# TLE985x register map
Vendor: Infineon Technologies AG; Series: MOTIX MCU; File version: 1.6
CPU: CM0 r0p0, little endian, no MPU, no FPU, 2 interrupt priority bits
Registers are 32-bit, read-write, no defined reset value unless marked. A register's access mark holds for its fields unless they carry their own. Offsets are from the block's base; [hi:lo] are bit positions; {n}, {i} and the like mark numbered series; 'fields as' and 'values as' point back to an identical list.

## ADC2
Base 0x4801C000
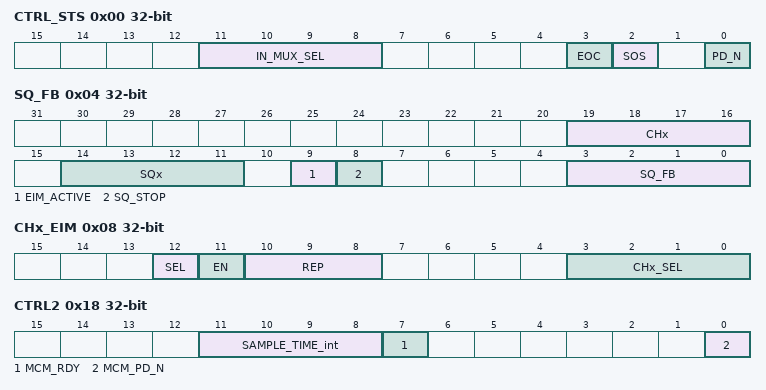
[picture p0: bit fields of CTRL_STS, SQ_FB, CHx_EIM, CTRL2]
0x00 CTRL_STS access per field — ADC2 Control and Status Register
  [11:8] IN_MUX_SEL rw — Channel for software mode
    {v}=CH{v}_EN (Channel {v} enable) (v=0..8)
  [3] EOC ro — ADC2 End of Conversion in software mode
    0=Pending (conversion still running); 1=Finished (conversion has finished)
  [2] SOS rw — ADC2 Start of Sampling/Conversion (software mode)
    0=Disable (no conversion is started); 1=Enable (conversion is started)
  [0] PD_N rw — ADC2 Power Down Signal
    0=POWER_DOWN (ADC2 is powered down); 1=ACTIVE (ADC2 is switched on)
0x04 SQ_FB ro — Sequencer Feedback Register
  [19:16] CHx — Current active ADC2 Channel (in normal mode)
    {v}=CH{v} (Channel {v}) (v=0..8)
  [14:11] SQx — Current active ADC2 Sequence (in normal mode)
    {v}=SQ{v} (Sequence {v}) (v=0..8); 9=SQ9 (Startup sequence)
  [9] EIM_ACTIVE — ADC2 EIM active
    0=not_active (EIM not active); 1=active (EIM active)
  [8] SQ_STOP — ADC2 Sequencer Stop Signal for DPP
    0=DPP_Running (Postprocessing Sequencer in running mode); 1=DPP_Stopped (Postprocessing Sequencer stopped / Software Mode entered)
  [3:0] SQ_FB — Current Sequence that caused software mode
    {v}=SQ{v} (Sequence {v}) (v=0..8); 11=CH_MASK (Sequence was 0 only after masking; SWM not entered); 12=SUSPEND (Debug Suspend Mode)
0x08 CHx_EIM — Channel Settings Bits for Exceptional Interrupt Measurement
  [12] SEL — Exceptional interrupt measurement (EIM) Trigger select
    0=GPT12PISEL_T3_GPT12_SEL (Signal according to SCU_GPT12PISEL.T3_GPT12SEL setting); 1=CP_clk (Charge-pump clock)
  [11] EN — Exceptional interrupt measurement (EIM) Trigger Event enable
    0=DISABLE (start of EIM disabled); 1=ENABLE (start of IEM enabled)
  [10:8] REP — Repeat count for exceptional interrupt measurement (EIM)
    0=Measurement (minimum or continuous measurement as long as trigger signals stays high, 1 / continuous SOC generated for ADC8); 1=Measurements (2 SOC generated for ADC8); 2=Measurements (4 SOC generated for ADC8); 3=Measurements (8 SOC generated for ADC8); 4=Measurements (16 SOC generated for ADC8); 5=Measurements (32 SOC generated for ADC8); 6=Measurements (64 SOC generated for ADC8); 7=Measurements (128 SOC generated for ADC8)
  [3:0] CHx_SEL — Channel set for exceptional interrupt measurement (EIM)
    {v}=CH{v}_EN (Channel {v} enable) (v=0..8)
0x10 MAX_TIME — Maximum Time for Software Mode
  [7:0] MAX_TIME — Maximum Time in Software Mode
    0=min (Software mode is not entered); 1=Software mode is active for 3 clock cycles; 255=max (Software mode is active for 257 clock cycles (typ. 12.85 us))
0x14 CTRL1 — Measurement Unit Control Register 1
  [8:0] CALIB_EN_8_0 — Calibration Enable for Channels 8 to 0
    1=CH0_EN (Channel 0 calibration enable); 2=CH1_EN (Channel 1 calibration enable); 4=CH2_EN (Channel 2 calibration enable); 8=CH3_EN (Channel 3 calibration enable); 16=CH4_EN (Channel 4 calibration enable); 32=CH5_EN (Channel 5 calibration enable); 64=CH6_EN (Channel 6 calibration enable); 128=CH7_EN (Channel 7 calibration enable); 0x100=CH8_EN (Channel 8 calibration enable)
0x18 CTRL2 access per field — Measurement Unit Control Register 2
  [11:8] SAMPLE_TIME_int rw — Sample time of ADC2
    0=MICLK4 (4 MI_CLK clock periods); 1=MICLK6 (6 MI_CLK clock periods); 2=MICLK8 (8 MI_CLK clock periods); 3=MICLK10 (10 MI_CLK clock periods); 4=MICLK12 (12 MI_CLK clock periods (default)); 5=MICLK14 (14 MI_CLK clock periods); 6=MICLK16 (16 MI_CLK clock periods); 7=MICLK18 (18 MI_CLK clock periods); 8=MICLK20 (20 MI_CLK clock periods); 9=MICLK22 (22 MI_CLK clock periods)
  [7] MCM_RDY ro — Ready Signal for MCM after Power On or Reset
    0=MCM_Not_Ready (Measurement Core Module in startup phase); 1=MCM_Ready (Measurement Core Module start-up phase finished)
  [0] MCM_PD_N rw — Power Down Signal for MCM
    0=MCM_Disabled (Measurement Core Module disabled); 1=MCM_Enabled (Measurement Core Module enabled)
0x1C CTRL4 — Measurement Unit Control Register 4
  [8:0] FILT_OUT_SEL_8_0 — Output Filter Selection for Channels 0 to 8
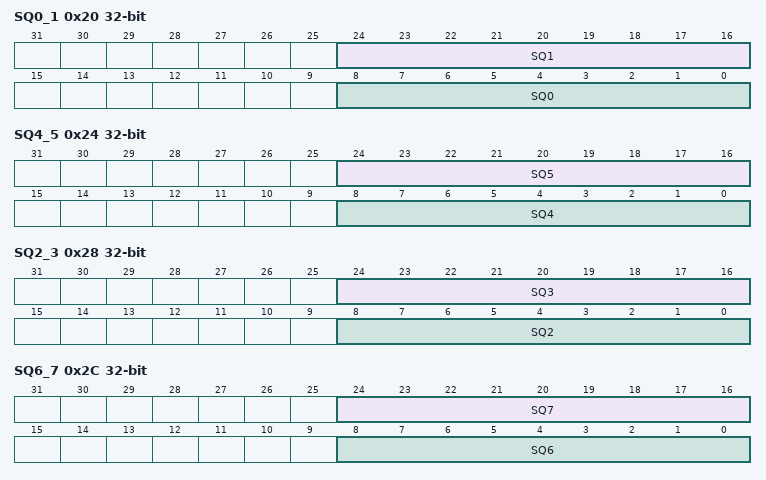
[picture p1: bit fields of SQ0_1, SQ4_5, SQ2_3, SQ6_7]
0x20 SQ0_1 — Measurement Channel Enable Bits for Sequence 0-1
  [24:16] SQ1 — Sequence 1 channel enable
    1=CH0_EN (Channel 0 enable); 2=CH1_EN (Channel 1 enable); 4=CH2_EN (Channel 2 enable); 8=CH3_EN (Channel 3 enable); 16=CH4_EN (Channel 4 enable); 32=CH5_EN (Channel 5 enable); 64=CH6_EN (Channel 6 enable); 128=CH7_EN (Channel 7 enable); 0x100=CH8_EN (Channel 8 enable)
  [8:0] SQ0 — Sequence 0 channel enable
    values as SQ1
0x24 SQ4_5 — Measurement Channel Enable Bits for Sequence 4 - 5
  [24:16] SQ5 — Sequence 5 channel enable
    values as SQ0_1.SQ1
  [8:0] SQ4 — Sequence 4 channel enable
    values as SQ0_1.SQ1
0x28 SQ2_3 — Measurement Channel Enable Bits for Sequence 2-3
  [24:16] SQ3 — Sequence 3 channel enable
    values as SQ0_1.SQ1
  [8:0] SQ2 — Sequence 2 channel enable
    values as SQ0_1.SQ1
0x2C SQ6_7 — Measurement Channel Enable Bits for Sequence 6 - 7
  [24:16] SQ7 — Sequence 7 channel enable
    values as SQ0_1.SQ1
  [8:0] SQ6 — Sequence 6 channel enable
    values as SQ0_1.SQ1
0x30 SQ8_9 — Measurement Channel Enable Bits for Sequence 8
  [8:0] SQ8 — Sequence 8 channel enable
    values as SQ0_1.SQ1
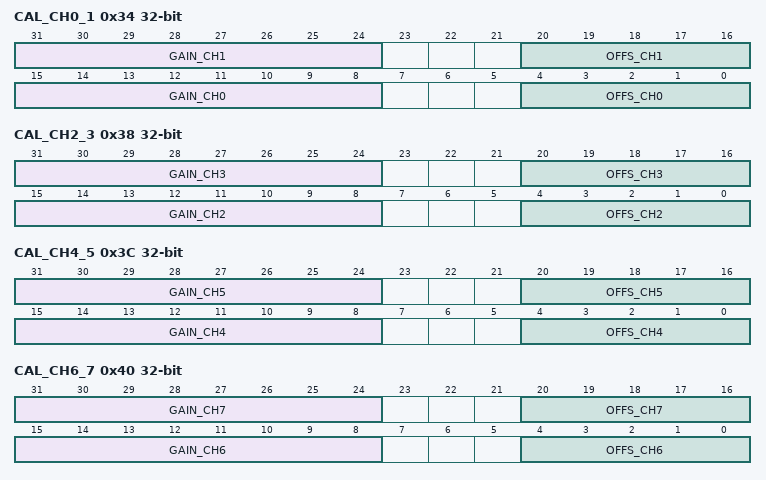
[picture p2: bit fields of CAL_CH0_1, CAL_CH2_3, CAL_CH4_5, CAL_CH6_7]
0x34 CAL_CH0_1 — Calibration for Channel 0 and 1
  [31:24] GAIN_CH1 — Gain Calibration for channel 1
  [20:16] OFFS_CH1 — Offset Calibration for channel 1
  [15:8] GAIN_CH0 — Gain Calibration for channel 0
  [4:0] OFFS_CH0 — Offset Calibration for channel 0
0x38 CAL_CH2_3 — Calibration for Channel 2 and 3
  [31:24] GAIN_CH3 — Gain Calibration for channel 3
  [20:16] OFFS_CH3 — Offset Calibration for channel 3
  [15:8] GAIN_CH2 — Gain Calibration for channel 2
  [4:0] OFFS_CH2 — Offset Calibration for channel 2
0x3C CAL_CH4_5 — Calibration for Channel 4 and 5
  [31:24] GAIN_CH5 — Gain Calibration for channel 5
  [20:16] OFFS_CH5 — Offset Calibration for channel 5
  [15:8] GAIN_CH4 — Gain Calibration for channel 4
  [4:0] OFFS_CH4 — Offset Calibration for channel 4
0x40 CAL_CH6_7 — Calibration for Channel 6 and 7
  [31:24] GAIN_CH7 — Gain Calibration for channel 7
  [20:16] OFFS_CH7 — Offset Calibration for channel 7
  [15:8] GAIN_CH6 — Gain Calibration for channel 6
  [4:0] OFFS_CH6 — Offset Calibration for channel 6
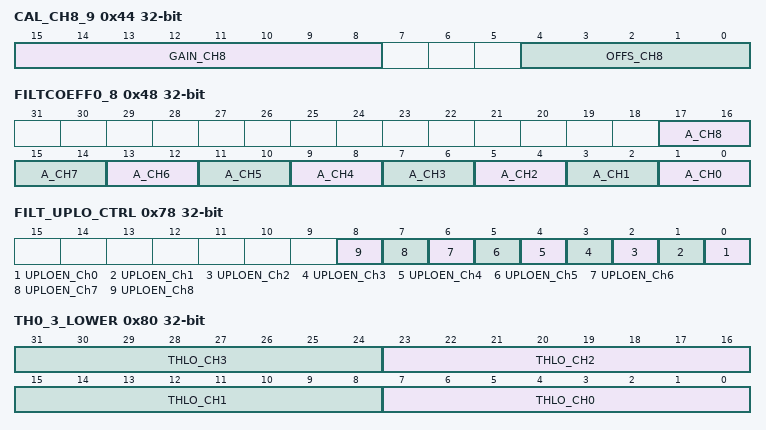
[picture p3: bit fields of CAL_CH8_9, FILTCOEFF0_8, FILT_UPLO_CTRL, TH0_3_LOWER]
0x44 CAL_CH8_9 — Calibration for Channel 8
  [15:8] GAIN_CH8 — Gain Calibration for channel 8
  [4:0] OFFS_CH8 — Offset Calibration for channel 8
0x48 FILTCOEFF0_8 — Filter Coefficients ADC Channel 0-8
  [all] fields
    0=1divBy2 (weight of current sample); 1=1divBy4 (weight of current sample); 2=1divBy8 (weight of current sample); 3=1divBy16 (weight of current sample)
  [2n+1:2n] A_CH{n} (n=0..8) — Filter Coefficient A for ADC channel {n}
{0x50+4i} FILT_OUT{i} ro (i=0..8) — ADC or Filter Output Channel {i}
  [9:0] OUT_CH{i} — ADC or filter output value channel {i}
0x78 FILT_UPLO_CTRL — Upper and Lower Threshold Filter Enable
  [all] fields
    0=Disable; 1=Enable
  [n] UPLOEN_Ch{n} (n=0..8) — Upper and lower threshold IIR filter enable ch {n}
0x80 TH0_3_LOWER — Lower Comparator Trigger Level Channel 0 -3
  [8n+7:8n] THLO_CH{n} (n=0..3) — Channel {n} lower trigger level
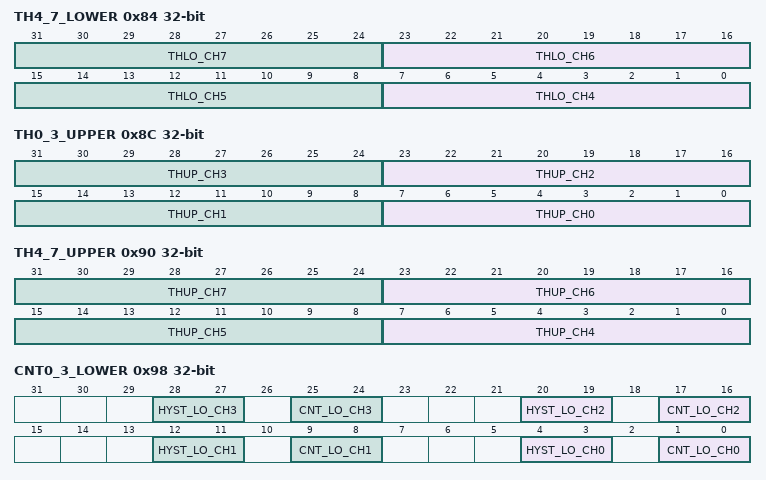
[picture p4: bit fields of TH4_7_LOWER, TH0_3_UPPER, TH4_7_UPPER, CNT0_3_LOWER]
0x84 TH4_7_LOWER — Lower Comparator Trigger Level Channel 4 to 7
  [8n-25:8n-32] THLO_CH{n} (n=4..7) — Channel {n} lower trigger level
0x88 TH8_11_LOWER — Lower Comparator Trigger Level Channel 8
  [7:0] THLO_CH8 — Channel 8 lower trigger level
0x8C TH0_3_UPPER — Upper Comparator Trigger Level Channel 0-3
  [8n+7:8n] THUP_CH{n} (n=0..3) — Channel {n} upper trigger level
0x90 TH4_7_UPPER — Upper Comparator Trigger Level Channel 4 -7
  [8n-25:8n-32] THUP_CH{n} (n=4..7) — Channel {n} upper trigger level
0x94 TH8_11_UPPER — Upper Comparator Trigger Level Channel 8
  [7:0] THUP_CH8 — Channel 8 upper trigger level
0x98 CNT0_3_LOWER — Lower Counter Trigger Level Channel 0 - 3
  [8n+4:8n+3] HYST_LO_CH{n} (n=0..3) — Channel {n} lower hysteresis
    0=HYSTOFF (hysteresis switched off); 1=HYST4 (hysteresis = 4); 2=HYST8 (hysteresis = 8); 3=HYST16 (hysteresis = 16)
  [8n+1:8n] CNT_LO_CH{n} (n=0..3) — Lower timer trigger threshold channel {n}
    0=1 measurement; 1=2 measurements; 2=4 measurements; 3=7 measurements
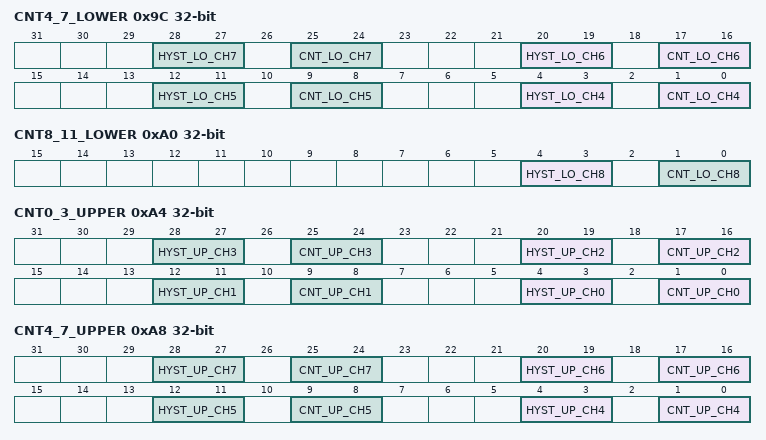
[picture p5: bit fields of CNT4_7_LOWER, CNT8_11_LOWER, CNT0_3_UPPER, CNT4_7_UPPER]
0x9C CNT4_7_LOWER — Lower Counter Trigger Level Channel 4 to 7
  [8n-28:8n-29] HYST_LO_CH{n} (n=4..7) — Channel {n} lower hysteresis
    values as CNT0_3_LOWER.HYST_LO_CH0
  [8n-31:8n-32] CNT_LO_CH{n} (n=4..7) — Lower timer trigger threshold channel {n}
    values as CNT0_3_LOWER.CNT_LO_CH0
0xA0 CNT8_11_LOWER — Lower Counter Trigger Level Channel 8
  [4:3] HYST_LO_CH8 — Channel 8 lower hysteresis
    values as CNT0_3_LOWER.HYST_LO_CH0
  [1:0] CNT_LO_CH8 — Lower timer trigger threshold channel 8
    values as CNT0_3_LOWER.CNT_LO_CH0
0xA4 CNT0_3_UPPER — Upper Counter Trigger Level Channel 0 - 3
  [8n+4:8n+3] HYST_UP_CH{n} (n=0..3) — Channel {n} upper hysteresis
    values as CNT0_3_LOWER.HYST_LO_CH0
  [8n+1:8n] CNT_UP_CH{n} (n=0..3) — Upper timer trigger threshold channel {n}
    values as CNT0_3_LOWER.CNT_LO_CH0
0xA8 CNT4_7_UPPER — Upper Counter Trigger Level Channel 4 to 7
  [8n-28:8n-29] HYST_UP_CH{n} (n=4..7) — Channel {n} upper hysteresis
    values as CNT0_3_LOWER.HYST_LO_CH0
  [8n-31:8n-32] CNT_UP_CH{n} (n=4..7) — Upper timer trigger threshold channel {n}
    values as CNT0_3_LOWER.CNT_LO_CH0
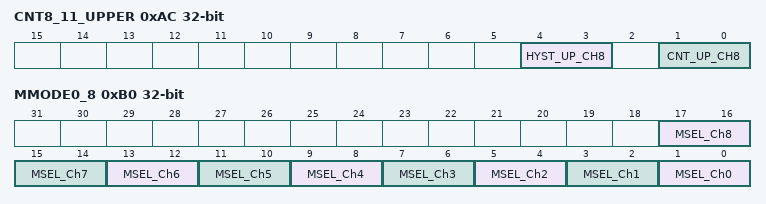
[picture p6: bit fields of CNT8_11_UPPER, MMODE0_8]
0xAC CNT8_11_UPPER — Upper Counter Trigger Level Channel 8
  [4:3] HYST_UP_CH8 — Channel 8 upper hysteresis
    values as CNT0_3_LOWER.HYST_LO_CH0
  [1:0] CNT_UP_CH8 — Upper timer trigger threshold channel 8
    values as CNT0_3_LOWER.CNT_LO_CH0
0xB0 MMODE0_8 — Measurement Mode of Ch 0-8
  [all] fields
    0=MMODE0 (upper and lower voltage/limit measurement); 1=MMODEUV (undervoltage/-limit measurement); 2=MMODEOV (overvoltage/-limit measurement)
  [2n+1:2n] MSEL_Ch{n} (n=0..8) — Measurement mode ch {n}
0xBC STATUS ro — ADC2 HV Status Register
  [1] READY — HVADC Ready bit
    0=Not_ready (Module in power down or in init phase); 1=Ready (set automatically 5 ADC clock cycles after module is enabled)
